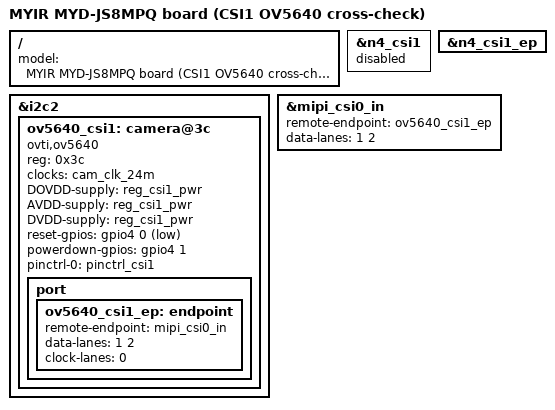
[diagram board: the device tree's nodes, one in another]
// SPDX-License-Identifier: (GPL-2.0+ OR MIT)
/*
 * MYD-JS8MPQ CSI1 cross-check variant: known-good OV5640 on the CSI1
 * connector instead of the default NVP6324/N4.
 *
 * Purpose: isolate the CSI1 link itself.  If the OV5640 produces a
 * clean image through the same CSI1 connector, FPC, mipi_csi_0 and ISI
 * path, the CSI1 channel is cleared and a fault is pinned to the
 * camera module under test.
 *
 * Pipeline: ov5640 (2-lane YUV) -> mipi_csi_0 -> isi_0 -> /dev/video*
 */

#include "myd-js8mpq-dsi.dts"

/ {
	model = "MYIR MYD-JS8MPQ board (CSI1 OV5640 cross-check)";
};

/* N4 off; its driver must not claim the shared reset/pwdn pins. */
&n4_csi1 {
	status = "disabled";
};

&n4_csi1_ep {
	/delete-property/ remote-endpoint;
};

&i2c2 {
	ov5640_csi1: camera@3c {
		compatible = "ovti,ov5640";
		reg = <0x3c>;
		clocks = <&cam_clk_24m>;
		clock-names = "xclk";
		DOVDD-supply = <&reg_csi1_pwr>;
		AVDD-supply = <&reg_csi1_pwr>;
		DVDD-supply = <&reg_csi1_pwr>;
		/* CSI1 pins, polarity per the 2026-06-05 OV5640-on-CSI1 probe */
		reset-gpios = <&gpio4 0 GPIO_ACTIVE_LOW>;
		powerdown-gpios = <&gpio4 1 GPIO_ACTIVE_HIGH>;
		pinctrl-names = "default";
		pinctrl-0 = <&pinctrl_csi1>;
		status = "okay";

		port {
			ov5640_csi1_ep: endpoint {
				remote-endpoint = <&mipi_csi0_in>;
				data-lanes = <1 2>;
				clock-lanes = <0>;
			};
		};
	};
};

/* Re-point CSI1 host at the OV5640, 2 lanes. */
&mipi_csi0_in {
	remote-endpoint = <&ov5640_csi1_ep>;
	data-lanes = <1 2>;
};
